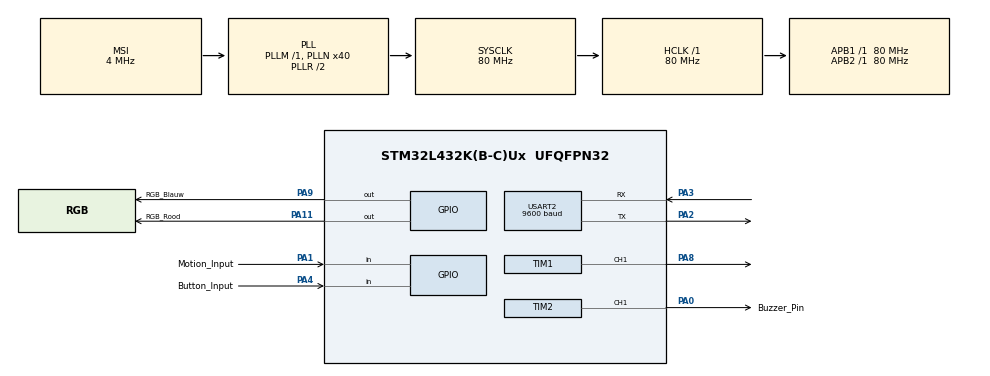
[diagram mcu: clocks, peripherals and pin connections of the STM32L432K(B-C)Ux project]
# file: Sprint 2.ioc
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Mcu.Family=STM32L4
Mcu.Name=STM32L432K(B-C)Ux
Mcu.Package=UFQFPN32
NVIC.PriorityGroup=NVIC_PRIORITYGROUP_4
PA0.GPIO_Label=Buzzer_Pin
PA0.Signal=S_TIM2_CH1
PA1.GPIO_Label=Motion_Input
PA1.Signal=GPIO_Input
PA11.GPIO_Label=RGB_Rood
PA11.Signal=GPIO_Output
PA2.Mode=Asynchronous
PA2.Signal=USART2_TX
PA3.Mode=Asynchronous
PA3.Signal=USART2_RX
PA4.GPIO_Label=Button_Input
PA4.GPIO_PuPd=GPIO_PULLUP
PA4.Signal=GPIO_Input
PA8.Signal=S_TIM1_CH1
PA9.GPIO_Label=RGB_Blauw
PA9.Signal=GPIO_Output
ProjectManager.HeapSize=0x200
ProjectManager.StackSize=0x400
ProjectManager.TargetToolchain=STM32CubeIDE
RCC.AHBFreq_Value=80000000
RCC.APB1Freq_Value=80000000
RCC.APB1TimFreq_Value=80000000
RCC.APB2Freq_Value=80000000
RCC.APB2TimFreq_Value=80000000
RCC.CortexFreq_Value=80000000
RCC.HCLKFreq_Value=80000000
RCC.HSE_VALUE=8000000
RCC.HSI48_VALUE=48000000
RCC.HSI_VALUE=16000000
RCC.LSE_VALUE=32768
RCC.MSI_VALUE=4000000
RCC.PLLN=40
RCC.SYSCLKFreq_VALUE=80000000
RCC.SYSCLKSource=RCC_SYSCLKSOURCE_PLLCLK
RCC.VCOOutputFreq_Value=160000000
SH.S_TIM1_CH1.0=TIM1_CH1,PWM Generation1 CH1
SH.S_TIM2_CH1.0=TIM2_CH1,PWM Generation1 CH1
TIM1.Channel-PWM\ Generation1\ CH1=TIM_CHANNEL_1
TIM1.Period=19999
TIM1.Prescaler=79
TIM1.Pulse-PWM\ Generation1\ CH1=1500
TIM2.Channel-PWM\ Generation1\ CH1=TIM_CHANNEL_1
TIM2.Period=999
TIM2.Prescaler=79
TIM2.Pulse-PWM\ Generation1\ CH1=500
USART2.BaudRate=9600
USART2.VirtualMode-Asynchronous=VM_ASYNC
board=custom

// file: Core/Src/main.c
/* USER CODE BEGIN Header */
/**
  ******************************************************************************
  * @file           : main.c
  * @brief          : Main program body
  ******************************************************************************
  * @attention
  *
  * Copyright (c) 2026 STMicroelectronics.
  * All rights reserved.
  *
  * This software is licensed under terms that can be found in the LICENSE file
  * in the root directory of this software component.
  * If no LICENSE file comes with this software, it is provided AS-IS.
  *
  ******************************************************************************
  */
/* USER CODE END Header */
#include "main.h"

TIM_HandleTypeDef htim1;
TIM_HandleTypeDef htim2;

UART_HandleTypeDef huart2;

/* USER CODE BEGIN PV */
uint8_t buzzer_aan = 0;
uint8_t vorige_knop = GPIO_PIN_SET;
/* USER CODE END PV */

void SystemClock_Config(void);
static void MX_GPIO_Init(void);
static void MX_TIM1_Init(void);
static void MX_USART2_UART_Init(void);
static void MX_TIM2_Init(void);

/* USER CODE BEGIN 0 */
void Servo_SetAngle(uint8_t angle)
{
    uint32_t pulse = 500 + ((uint32_t)angle * 2000) / 180;
    __HAL_TIM_SET_COMPARE(&htim1, TIM_CHANNEL_1, pulse);
}

void Buzzer_Nood(void)
{
	 // Hoge toon (1000 Hz)
	    __HAL_TIM_SET_AUTORELOAD(&htim2, 999);
	    __HAL_TIM_SET_COMPARE(&htim2, TIM_CHANNEL_1, 500);
	    __HAL_TIM_SET_COUNTER(&htim2, 0); // reset teller
	    HAL_TIM_PWM_Start(&htim2, TIM_CHANNEL_1);
	    HAL_Delay(300);
	    HAL_TIM_PWM_Stop(&htim2, TIM_CHANNEL_1);

	    // Lage toon (500 Hz)
	    __HAL_TIM_SET_AUTORELOAD(&htim2, 1999);
	    __HAL_TIM_SET_COMPARE(&htim2, TIM_CHANNEL_1, 1000);
	    __HAL_TIM_SET_COUNTER(&htim2, 0); // reset teller
	    HAL_TIM_PWM_Start(&htim2, TIM_CHANNEL_1);
	    HAL_Delay(300);
	    HAL_TIM_PWM_Stop(&htim2, TIM_CHANNEL_1);
}
/* USER CODE END 0 */

int main(void)
{

  /* MCU Configuration--------------------------------------------------------*/

  /* Reset of all peripherals, Initializes the Flash interface and the Systick. */
  HAL_Init();

  /* Configure the system clock */
  SystemClock_Config();

  /* Initialize all configured peripherals */
  MX_GPIO_Init();
  MX_TIM1_Init();
  MX_USART2_UART_Init();
  MX_TIM2_Init();
  /* USER CODE BEGIN 2 */
  HAL_TIM_PWM_Start(&htim1, TIM_CHANNEL_1);
  __HAL_TIM_MOE_ENABLE(&htim1);

  HAL_TIM_PWM_Start(&htim1, TIM_CHANNEL_1);
  __HAL_TIM_MOE_ENABLE(&htim1);

  /* USER CODE END 2 */

  /* Infinite loop */
  while (1)
  {

    /* USER CODE BEGIN 3 */

	  uint8_t huidige_knop = HAL_GPIO_ReadPin(Button_Input_GPIO_Port, Button_Input_Pin);

	  if (huidige_knop == GPIO_PIN_RESET && vorige_knop == GPIO_PIN_SET)
	  {
	      // Wacht tot knop losgelaten is
	      while (HAL_GPIO_ReadPin(Button_Input_GPIO_Port, Button_Input_Pin) == GPIO_PIN_RESET);
	      HAL_Delay(50); // debounce

	      buzzer_aan = !buzzer_aan;
	      if (buzzer_aan)
	      {
	          char aan[] = "Buzzer aan\r\n";
	          HAL_UART_Transmit(&huart2, (uint8_t*)aan, sizeof(aan)-1, HAL_MAX_DELAY);
	      }
	      else
	      {
	          HAL_TIM_PWM_Stop(&htim2, TIM_CHANNEL_1);
	          char uit[] = "Buzzer uit\r\n";
	          HAL_UART_Transmit(&huart2, (uint8_t*)uit, sizeof(uit)-1, HAL_MAX_DELAY);
	      }
	  }
	  vorige_knop = huidige_knop;

	  if (buzzer_aan)
	  {
	      Buzzer_Nood();
	  }

	   if (HAL_GPIO_ReadPin(Motion_Input_GPIO_Port, Motion_Input_Pin) == GPIO_PIN_SET)
	   {
	       char Beweging[] = "Beweging gedetecteerd\r\n";
	       HAL_UART_Transmit(&huart2, (uint8_t*)Beweging, sizeof(Beweging)-1, HAL_MAX_DELAY);

	       Servo_SetAngle(180);
	       HAL_Delay(3000);
	       Servo_SetAngle(0);
	       HAL_Delay(1000);

	       HAL_GPIO_WritePin(RGB_Blauw_GPIO_Port, RGB_Blauw_Pin, GPIO_PIN_SET);
	       HAL_Delay(1000);
	       HAL_GPIO_WritePin(RGB_Blauw_GPIO_Port, RGB_Blauw_Pin, GPIO_PIN_RESET);
	       HAL_GPIO_WritePin(RGB_Groen_GPIO_Port, RGB_Groen_Pin, GPIO_PIN_SET);
	       HAL_Delay(1000);
	       HAL_GPIO_WritePin(RGB_Groen_GPIO_Port, RGB_Groen_Pin, GPIO_PIN_RESET);
	       HAL_GPIO_WritePin(RGB_Rood_GPIO_Port, RGB_Rood_Pin, GPIO_PIN_SET);
	       HAL_Delay(1000);
	       HAL_GPIO_WritePin(RGB_Rood_GPIO_Port, RGB_Rood_Pin, GPIO_PIN_RESET);
	   }

  }
  /* USER CODE END 3 */
}

void SystemClock_Config(void)
{
  RCC_OscInitTypeDef RCC_OscInitStruct = {0};
  RCC_ClkInitTypeDef RCC_ClkInitStruct = {0};

  /** Configure the main internal regulator output voltage
  */
  if (HAL_PWREx_ControlVoltageScaling(PWR_REGULATOR_VOLTAGE_SCALE1) != HAL_OK)
  {
    Error_Handler();
  }

  /** Initializes the RCC Oscillators according to the specified parameters
  * in the RCC_OscInitTypeDef structure.
  */
  RCC_OscInitStruct.OscillatorType = RCC_OSCILLATORTYPE_MSI;
  RCC_OscInitStruct.MSIState = RCC_MSI_ON;
  RCC_OscInitStruct.MSICalibrationValue = 0;
  RCC_OscInitStruct.MSIClockRange = RCC_MSIRANGE_6;
  RCC_OscInitStruct.PLL.PLLState = RCC_PLL_ON;
  RCC_OscInitStruct.PLL.PLLSource = RCC_PLLSOURCE_MSI;
  RCC_OscInitStruct.PLL.PLLM = 1;
  RCC_OscInitStruct.PLL.PLLN = 40;
  RCC_OscInitStruct.PLL.PLLP = RCC_PLLP_DIV7;
  RCC_OscInitStruct.PLL.PLLQ = RCC_PLLQ_DIV2;
  RCC_OscInitStruct.PLL.PLLR = RCC_PLLR_DIV2;
  if (HAL_RCC_OscConfig(&RCC_OscInitStruct) != HAL_OK)
  {
    Error_Handler();
  }

  /** Initializes the CPU, AHB and APB buses clocks
  */
  RCC_ClkInitStruct.ClockType = RCC_CLOCKTYPE_HCLK|RCC_CLOCKTYPE_SYSCLK
                              |RCC_CLOCKTYPE_PCLK1|RCC_CLOCKTYPE_PCLK2;
  RCC_ClkInitStruct.SYSCLKSource = RCC_SYSCLKSOURCE_PLLCLK;
  RCC_ClkInitStruct.AHBCLKDivider = RCC_SYSCLK_DIV1;
  RCC_ClkInitStruct.APB1CLKDivider = RCC_HCLK_DIV1;
  RCC_ClkInitStruct.APB2CLKDivider = RCC_HCLK_DIV1;

  if (HAL_RCC_ClockConfig(&RCC_ClkInitStruct, FLASH_LATENCY_4) != HAL_OK)
  {
    Error_Handler();
  }
}

static void MX_TIM1_Init(void)
{

  TIM_MasterConfigTypeDef sMasterConfig = {0};
  TIM_OC_InitTypeDef sConfigOC = {0};
  TIM_BreakDeadTimeConfigTypeDef sBreakDeadTimeConfig = {0};

  htim1.Instance = TIM1;
  htim1.Init.Prescaler = 79;
  htim1.Init.CounterMode = TIM_COUNTERMODE_UP;
  htim1.Init.Period = 19999;
  htim1.Init.ClockDivision = TIM_CLOCKDIVISION_DIV1;
  htim1.Init.RepetitionCounter = 0;
  htim1.Init.AutoReloadPreload = TIM_AUTORELOAD_PRELOAD_DISABLE;
  if (HAL_TIM_PWM_Init(&htim1) != HAL_OK)
  {
    Error_Handler();
  }
  sMasterConfig.MasterOutputTrigger = TIM_TRGO_RESET;
  sMasterConfig.MasterOutputTrigger2 = TIM_TRGO2_RESET;
  sMasterConfig.MasterSlaveMode = TIM_MASTERSLAVEMODE_DISABLE;
  if (HAL_TIMEx_MasterConfigSynchronization(&htim1, &sMasterConfig) != HAL_OK)
  {
    Error_Handler();
  }
  sConfigOC.OCMode = TIM_OCMODE_PWM1;
  sConfigOC.Pulse = 1500;
  sConfigOC.OCPolarity = TIM_OCPOLARITY_HIGH;
  sConfigOC.OCNPolarity = TIM_OCNPOLARITY_HIGH;
  sConfigOC.OCFastMode = TIM_OCFAST_DISABLE;
  sConfigOC.OCIdleState = TIM_OCIDLESTATE_RESET;
  sConfigOC.OCNIdleState = TIM_OCNIDLESTATE_RESET;
  if (HAL_TIM_PWM_ConfigChannel(&htim1, &sConfigOC, TIM_CHANNEL_1) != HAL_OK)
  {
    Error_Handler();
  }
  sBreakDeadTimeConfig.OffStateRunMode = TIM_OSSR_DISABLE;
  sBreakDeadTimeConfig.OffStateIDLEMode = TIM_OSSI_DISABLE;
  sBreakDeadTimeConfig.LockLevel = TIM_LOCKLEVEL_OFF;
  sBreakDeadTimeConfig.DeadTime = 0;
  sBreakDeadTimeConfig.BreakState = TIM_BREAK_DISABLE;
  sBreakDeadTimeConfig.BreakPolarity = TIM_BREAKPOLARITY_HIGH;
  sBreakDeadTimeConfig.BreakFilter = 0;
  sBreakDeadTimeConfig.Break2State = TIM_BREAK2_DISABLE;
  sBreakDeadTimeConfig.Break2Polarity = TIM_BREAK2POLARITY_HIGH;
  sBreakDeadTimeConfig.Break2Filter = 0;
  sBreakDeadTimeConfig.AutomaticOutput = TIM_AUTOMATICOUTPUT_DISABLE;
  if (HAL_TIMEx_ConfigBreakDeadTime(&htim1, &sBreakDeadTimeConfig) != HAL_OK)
  {
    Error_Handler();
  }
  HAL_TIM_MspPostInit(&htim1);

}

static void MX_TIM2_Init(void)
{

  TIM_MasterConfigTypeDef sMasterConfig = {0};
  TIM_OC_InitTypeDef sConfigOC = {0};

  htim2.Instance = TIM2;
  htim2.Init.Prescaler = 79;
  htim2.Init.CounterMode = TIM_COUNTERMODE_UP;
  htim2.Init.Period = 999;
  htim2.Init.ClockDivision = TIM_CLOCKDIVISION_DIV1;
  htim2.Init.AutoReloadPreload = TIM_AUTORELOAD_PRELOAD_DISABLE;
  if (HAL_TIM_PWM_Init(&htim2) != HAL_OK)
  {
    Error_Handler();
  }
  sMasterConfig.MasterOutputTrigger = TIM_TRGO_RESET;
  sMasterConfig.MasterSlaveMode = TIM_MASTERSLAVEMODE_DISABLE;
  if (HAL_TIMEx_MasterConfigSynchronization(&htim2, &sMasterConfig) != HAL_OK)
  {
    Error_Handler();
  }
  sConfigOC.OCMode = TIM_OCMODE_PWM1;
  sConfigOC.Pulse = 500;
  sConfigOC.OCPolarity = TIM_OCPOLARITY_HIGH;
  sConfigOC.OCFastMode = TIM_OCFAST_DISABLE;
  if (HAL_TIM_PWM_ConfigChannel(&htim2, &sConfigOC, TIM_CHANNEL_1) != HAL_OK)
  {
    Error_Handler();
  }
  HAL_TIM_MspPostInit(&htim2);

}

static void MX_USART2_UART_Init(void)
{

  huart2.Instance = USART2;
  huart2.Init.BaudRate = 9600;
  huart2.Init.WordLength = UART_WORDLENGTH_8B;
  huart2.Init.StopBits = UART_STOPBITS_1;
  huart2.Init.Parity = UART_PARITY_NONE;
  huart2.Init.Mode = UART_MODE_TX_RX;
  huart2.Init.HwFlowCtl = UART_HWCONTROL_NONE;
  huart2.Init.OverSampling = UART_OVERSAMPLING_16;
  huart2.Init.OneBitSampling = UART_ONE_BIT_SAMPLE_DISABLE;
  huart2.AdvancedInit.AdvFeatureInit = UART_ADVFEATURE_NO_INIT;
  if (HAL_UART_Init(&huart2) != HAL_OK)
  {
    Error_Handler();
  }

}

static void MX_GPIO_Init(void)
{
  GPIO_InitTypeDef GPIO_InitStruct = {0};

  /* GPIO Ports Clock Enable */
  __HAL_RCC_GPIOA_CLK_ENABLE();

  /*Configure GPIO pin Output Level */
  HAL_GPIO_WritePin(GPIOA, RGB_Blauw_Pin|RGB_Groen_Pin|RGB_Rood_Pin, GPIO_PIN_RESET);

  /*Configure GPIO pin : Motion_Input_Pin */
  GPIO_InitStruct.Pin = Motion_Input_Pin;
  GPIO_InitStruct.Mode = GPIO_MODE_INPUT;
  GPIO_InitStruct.Pull = GPIO_NOPULL;
  HAL_GPIO_Init(Motion_Input_GPIO_Port, &GPIO_InitStruct);

  /*Configure GPIO pin : Button_Input_Pin */
  GPIO_InitStruct.Pin = Button_Input_Pin;
  GPIO_InitStruct.Mode = GPIO_MODE_INPUT;
  GPIO_InitStruct.Pull = GPIO_PULLUP;
  HAL_GPIO_Init(Button_Input_GPIO_Port, &GPIO_InitStruct);

  /*Configure GPIO pins : RGB_Blauw_Pin RGB_Groen_Pin RGB_Rood_Pin */
  GPIO_InitStruct.Pin = RGB_Blauw_Pin|RGB_Groen_Pin|RGB_Rood_Pin;
  GPIO_InitStruct.Mode = GPIO_MODE_OUTPUT_PP;
  GPIO_InitStruct.Pull = GPIO_NOPULL;
  GPIO_InitStruct.Speed = GPIO_SPEED_FREQ_LOW;
  HAL_GPIO_Init(GPIOA, &GPIO_InitStruct);

}

void Error_Handler(void)
{
  __disable_irq();
  while (1)
  {
  }
}
